# R7FA8M1AH register map
Vendor: Renesas; Series: RA8; File version: 1.2
CPU: CM85 r0p0, little endian, MPU, FPU, VTOR, 4 interrupt priority bits
Registers are 32-bit, read-write, reset 0x0 unless marked. A register's access mark holds for its fields unless they carry their own. Offsets are from the block's base; [hi:lo] are bit positions; {n}, {i} and the like mark numbered series; 'fields as' and 'values as' point back to an identical list.

## RTC — Realtime Clock
Base 0x40202000
Same registers: RTC_NS 0x50202000
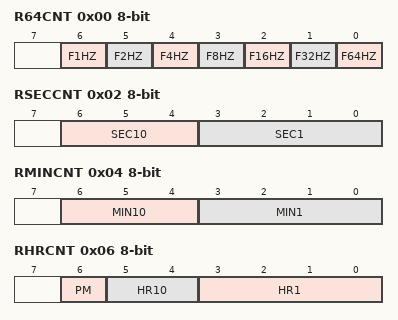
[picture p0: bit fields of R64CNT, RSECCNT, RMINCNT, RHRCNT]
0x00 R64CNT 8-bit ro (reset mask 0x80) — 64-Hz Counter
  [6] F1HZ — 1Hz
  [5] F2HZ — 2Hz
  [4] F4HZ — 4Hz
  [3] F8HZ — 8Hz
  [2] F16HZ — 16Hz
  [1] F32HZ — 32Hz
  [0] F64HZ — 64Hz
0x02 BCNT0 8-bit reset not defined (alternate view of RSECCNT) — Binary Counter 0
  [7:0] BCNT0 — The BCNT0 counter is a readable/writable 32-bit binary counter b7 to b0.
0x02 RSECCNT 8-bit reset not defined — Second Counter
  [6:4] SEC10 — 10-Second Count Counts from 0 to 5 for 60-second counting.
  [3:0] SEC1 — 1-Second Count Counts from 0 to 9 every second. When a carry is generated, 1 is added to the tens place.
0x04 BCNT1 8-bit reset not defined (alternate view of RMINCNT) — Binary Counter 1
  [7:0] BCNT1 — The BCNT1 counter is a readable/writable 32-bit binary counter b15 to b8.
0x04 RMINCNT 8-bit reset not defined — Minute Counter
  [6:4] MIN10 — 10-Minute Count Counts from 0 to 5 for 60-minute counting.
  [3:0] MIN1 — 1-Minute Count Counts from 0 to 9 every minute. When a carry is generated, 1 is added to the tens place.
0x06 BCNT2 8-bit reset not defined (alternate view of RHRCNT) — Binary Counter 2
  [7:0] BCNT2 — The BCNT2 counter is a readable/writable 32-bit binary counter b23 to b16.
0x06 RHRCNT 8-bit reset not defined — Hour Counter
  [6] PM — Time Counter Setting for a.m./p.m.
    0=a.m; 1=p.m
  [5:4] HR10 — 10-Hour Count Counts from 0 to 2 once per carry from the ones place.
  [3:0] HR1 — 1-Hour Count Counts from 0 to 9 once per hour. When a carry is generated, 1 is added to the tens place.
0x08 BCNT3 8-bit reset not defined (alternate view of RWKCNT) — Binary Counter 3
  [7:0] BCNT3 — The BCNT3 counter is a readable/writable 32-bit binary counter b31 to b24.
0x08 RWKCNT 8-bit reset not defined — Day-of-Week Counter
  [2:0] DAYW — Day-of-Week Counting
    0=Sunday; 1=Monday; 2=Tuesday; 3=Wednesday; 4=Thursday; 5=Friday; 6=Saturday; 7=Setting Prohibited
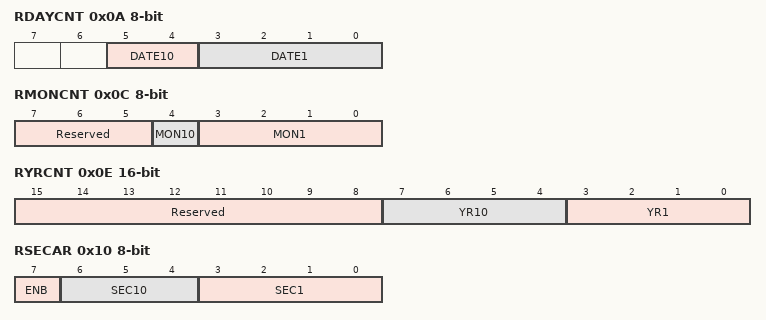
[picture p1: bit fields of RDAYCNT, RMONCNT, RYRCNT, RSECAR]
0x0A RDAYCNT 8-bit (reset mask 0xC0) — Day Counter
  [5:4] DATE10 — 10-Day Count Counts from 0 to 3 once per carry from the ones place.
  [3:0] DATE1 — 1-Day Count Counts from 0 to 9 once per day. When a carry is generated, 1 is added to the tens place.
0x0C RMONCNT 8-bit (reset mask 0xE0) — Month Counter
  [7:5] Reserved — These bits are read as 000. The write value should be 000.
  [4] MON10 — 10-Month Count Counts from 0 to 1 once per carry from the ones place.
  [3:0] MON1 — 1-Month Count Counts from 0 to 9 once per month. When a carry is generated, 1 is added to the tens place.
0x0E RYRCNT 16-bit (reset mask 0xFF00) — Year Counter
  [15:8] Reserved — These bits are read as 00000000. The write value should be 00000000.
  [7:4] YR10 — 10-Year Count Counts from 0 to 9 once per carry from ones place. When a carry is generated in the tens place, 1 is added to the hundreds place.
  [3:0] YR1 — 1-Year Count Counts from 0 to 9 once per year. When a carry is generated, 1 is added to the tens place.
0x10 BCNT0AR 8-bit reset not defined (alternate view of RSECAR) — Binary Counter 0 Alarm Register
  [7:0] BCNT0AR — he BCNT0AR counter is a readable/writable alarm register corresponding to 32-bit binary counter b7 to b0.
0x10 RSECAR 8-bit reset not defined — Second Alarm Register
  [7] ENB — Compare enable
    0=The register value is not compared with the RSECCNT counter value; 1=The register value is compared with the RSECCNT counter value
  [6:4] SEC10 — 10-Seconds Value for the tens place of seconds
  [3:0] SEC1 — 1-Second Value for the ones place of seconds
0x12 BCNT1AR 8-bit reset not defined (alternate view of RMINAR) — Binary Counter 1 Alarm Register
  [7:0] BCNT1AR — he BCNT1AR counter is a readable/writable alarm register corresponding to 32-bit binary counter b15 to b8.
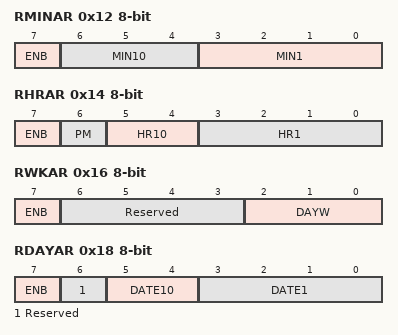
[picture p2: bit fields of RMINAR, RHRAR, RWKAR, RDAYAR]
0x12 RMINAR 8-bit reset not defined — Minute Alarm Register
  [7] ENB — Compare enable
    0=The register value is not compared with the RMINCNT counter value; 1=The register value is compared with the RMINCNT counter value
  [6:4] MIN10 — 10-Minute Count Value for the tens place of minutes
  [3:0] MIN1 — 1-Minute Count Value for the ones place of minutes
0x14 BCNT2AR 8-bit reset not defined (alternate view of RHRAR) — Binary Counter 2 Alarm Register
  [7:0] BCNT2AR — The BCNT2AR counter is a readable/writable 32-bit binary counter b23 to b16.
0x14 RHRAR 8-bit reset not defined — Hour Alarm Register
  [7] ENB — Compare enable
    0=The register value is not compared with the RHRCNT counter value; 1=The register value is compared with the RHRCNT counter value
  [6] PM — Time Counter Setting for a.m./p.m.
    0=a.m; 1=p.m
  [5:4] HR10 — 10-Hour Count Value for the tens place of hours
  [3:0] HR1 — 1-Hour Count Value for the ones place of hours
0x16 BCNT3AR 8-bit reset not defined (alternate view of RWKAR) — Binary Counter 3 Alarm Register
  [7:0] BCNT3AR — The BCNT3AR counter is a readable/writable 32-bit binary counter b31 to b24.
0x16 RWKAR 8-bit reset not defined — Day-of-Week Alarm Register
  [7] ENB — Compare enable
    0=The register value is not compared with the RWKCNT counter value; 1=The register value is compared with the RWKCNT counter value
  [6:3] Reserved — These bits are read as 0000. The write value should be 0000.
  [2:0] DAYW — Day-of-Week Counting
    values as RWKCNT.DAYW
0x18 BCNT0AER 8-bit reset not defined (alternate view of RDAYAR) — Binary Counter 0 Alarm Enable Register
  [7:0] ENB — The BCNT0AER register is a readable/writable register for setting the alarm enable corresponding to 32-bit binary counter b7 to b0.
0x18 RDAYAR 8-bit reset not defined — Date Alarm Register
  [7] ENB — Compare enable
    0=The register value is not compared with the RDAYCNT counter value; 1=The register value is compared with the RDAYCNT counter value
  [6] Reserved — This bit is read as 0. The write value should be 0.
  [5:4] DATE10 — 10 Days Value for the tens place of days
  [3:0] DATE1 — 1 Day Value for the ones place of days
0x1A BCNT1AER 8-bit reset not defined (alternate view of RMONAR) — Binary Counter 1 Alarm Enable Register
  [7:0] ENB — The BCNT1AER register is a readable/writable register for setting the alarm enable corresponding to 32-bit binary counter b15 to b8.
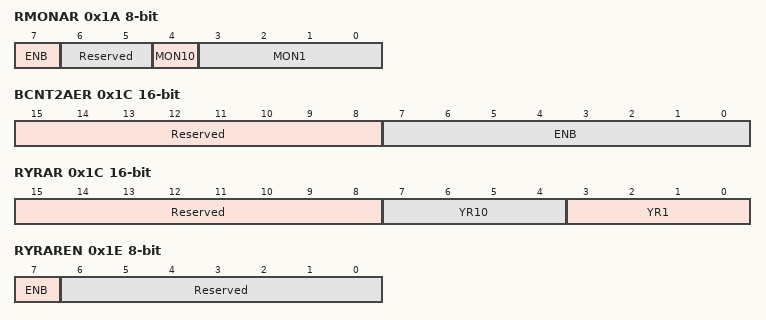
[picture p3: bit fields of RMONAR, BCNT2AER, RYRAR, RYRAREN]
0x1A RMONAR 8-bit reset not defined — Month Alarm Register
  [7] ENB — Compare enable
    0=The register value is not compared with the RMONCNT counter value; 1=The register value is compared with the RMONCNT counter value
  [6:5] Reserved — These bits are read as 00. The write value should be 00.
  [4] MON10 — 10 Months Value for the tens place of months
  [3:0] MON1 — 1 Month Value for the ones place of months
0x1C BCNT2AER 16-bit (reset mask 0xFF00) (alternate view of RYRAR) — Binary Counter 2 Alarm Enable Register
  [15:8] Reserved — These bits are read as 00000000. The write value should be 00000000.
  [7:0] ENB — The BCNT2AER register is a readable/writable register for setting the alarm enable corresponding to 32-bit binary counter b23 to b16.
0x1C RYRAR 16-bit (reset mask 0xFF00) — Year Alarm Register
  [15:8] Reserved — These bits are read as 00000000. The write value should be 00000000.
  [7:4] YR10 — 10 Years Value for the tens place of years
  [3:0] YR1 — 1 Year Value for the ones place of years
0x1E BCNT3AER 8-bit reset not defined (alternate view of RYRAREN) — Binary Counter 3 Alarm Enable Register
  [7:0] ENB — The BCNT3AER register is a readable/writable register for setting the alarm enable corresponding to 32-bit binary counter b31 to b24.
0x1E RYRAREN 8-bit reset not defined — Year Alarm Enable Register
  [7] ENB — Compare enable
    0=The register value is not compared with the RYRCNT counter value; 1=The register value is compared with the RYRCNT counter value
  [6:0] Reserved — These bits are read as 0000000. The write value should be 0000000.
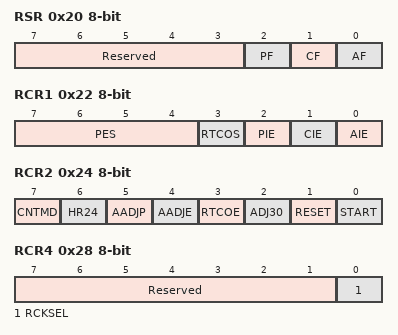
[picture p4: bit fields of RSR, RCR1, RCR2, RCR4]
0x20 RSR 8-bit (reset mask 0x7) — RTC Start Register
  [7:3] Reserved — These bits are read as 00000. The write value should be 00000.
  [2] PF — Interrupt period
  [1] CF — Carry flag
  [0] AF — Alarm flag
0x22 RCR1 8-bit (reset mask 0xA) — RTC Control Register 1
  [7:4] PES — Periodic Interrupt Select
    6=A periodic interrupt is generated every 1/256 second((RCR4.RCKSEL = 0)./A periodic interrupt is generated every 1/128 second((RCR4.RCKSEL = 1); 7=A periodic interrupt is generated every 1/128 second; 8=A periodic interrupt is generated every 1/64 second; 9=A periodic interrupt is generated every 1/32 second; 10=A periodic interrupt is generated every 1/16 second; 11=A periodic interrupt is generated every 1/8 second; 12=A periodic interrupt is generated every 1/4 second; 13=A periodic interrupt is generated every 1/2 second; 14=A periodic interrupt is generated every 1 second; 15=A periodic interrupt is generated every 2 seconds; other=others (No periodic interrupts are generated.)
  [3] RTCOS — RTCOUT Output Select
    0=RTCOUT outputs 1 Hz; 1=RTCOUT outputs 64 Hz
  [2] PIE — Periodic Interrupt Enable
    0=A periodic interrupt request is disabled; 1=A periodic interrupt request is enabled
  [1] CIE — Carry Interrupt Enable
    0=A carry interrupt request is disabled; 1=A carry interrupt request is enabled
  [0] AIE — Alarm Interrupt Enable
    0=An alarm interrupt request is disabled; 1=An alarm interrupt request is enabled
0x24 RCR2 8-bit (reset mask 0xE) — RTC Control Register 2
  [7] CNTMD — Count Mode Select
    0=The calendar count mode; 1=The binary count mode
  [6] HR24 — Hours Mode
    0=The RTC operates in 12-hour mode; 1=The RTC operates in 24-hour mode
  [5] AADJP — Automatic Adjustment Period Select (When the LOCO clock is selected, the setting of this bit is disabled.)
    0=The RADJ.ADJ[5:0] setting value is adjusted from the count value of the prescaler every minute; 1=The RADJ.ADJ[5:0] setting value is adjusted from the count value of the prescaler every 10 seconds
  [4] AADJE — Automatic Adjustment Enable (When the LOCO clock is selected, the setting of this bit is disabled.)
    0=Automatic adjustment is disabled; 1=Automatic adjustment is enabled
  [3] RTCOE — RTCOUT Output Enable
    0=RTCOUT output disabled; 1=RTCOUT output enabled
  [2] ADJ30 — 30-Second Adjustment
    0=Writing is invalid.(write) / In normal time operation, or 30-second adjustment has completed.(read); 1=30-second adjustment is executed.(write) / During 30-second adjustment.(read)
  [1] RESET — RTC Software Reset
    0=Writing is invalid.(write) / In normal time operation, or an RTC software reset has completed.(read); 1=The prescaler and the target registers for RTC software reset *1 are initialized.(write) / During an RTC software reset.(read)
  [0] START
    0=Prescaler and time counter are stopped; 1=Prescaler and time counter operate normally
0x26 RCR3 8-bit — RTC Control Register 3
0x28 RCR4 8-bit (reset mask 0xFE) — RTC Control Register 4
  [7:1] Reserved — These bits are read as 0000000. The write value should be 0000000.
  [0] RCKSEL — Count Source Select
    0=Sub-clock oscillator is selected; 1=LOCO clock oscillator is selected
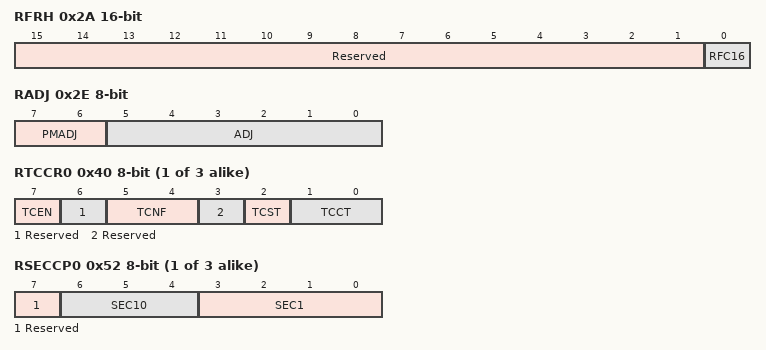
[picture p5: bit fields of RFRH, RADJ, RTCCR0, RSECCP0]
0x2A RFRH 16-bit (reset mask 0xFFFE) — Frequency Register H
  [15:1] Reserved — These bits are read as 000000000000000. The write value should be 000000000000000.
  [0] RFC16 — Frequency Comparison Value (b16) To generate the operating clock from the LOCOclock, this bit sets the comparison value of the 128-Hz clock cycle.
0x2C RFRL 16-bit reset not defined — Frequency Register L
  [15:0] RFC — Frequency Comparison Value(b15-b0) To generate the operating clock from the main clock, this bit sets the comparison value of the 128-Hz clock cycle.
0x2E RADJ 8-bit reset not defined — Time Error Adjustment Register
  [7:6] PMADJ — Plus-Minus
    0=Adjustment is not performed; 1=Adjustment is performed by the addition to the prescaler; 2=Adjustment is performed by the subtraction from the prescaler; 3=Setting prohibited
  [5:0] ADJ — Adjustment Value These bits specify the adjustment value from the prescaler.
0x32 RTEST 8-bit
0x38 RKEY 8-bit
{0x40+2i} RTCCR{i} (i=0..2) 8-bit reset not defined — Time Capture Control Register {i}
  [7] TCEN — Time Capture Event Input Pin Enable
    0=The RTCIC pin is disabled as the time capture event input; 1=The RTCIC pin is enabled as the time capture event input
  [6] Reserved — This bit is read as 0. The write value should be 0.
  [5:4] TCNF — Time Capture Noise Filter Control
    0=The noise filter is off; 1=Setting prohibited; 2=The noise filter is on (count source); 3=The noise filter is on (count source by divided by 32)
  [3] Reserved — This bit is read as 0. The write value should be 0.
  [2] TCST write-0-clears read-modifies — Time Capture Status
    0=No event is detected; 1=An event is detected
  [1:0] TCCT — Time Capture Control
    0=No event is detected; 1=Rising edge is detected; 2=Falling edge is detected; 3=Both edges are detected
{0x52+0x10*i} BCNT0CP{i} (i=0..2) 8-bit ro reset not defined (alternate view of RSECCP{i}) — BCNT0 Capture Register {i}
  [7:0] BCNT0CP — BCNT0CP is a read-only register that captures the BCNT0 value when a time capture event is detected.
{0x52+0x10*i} RSECCP{i} (i=0..2) 8-bit ro reset not defined — Second Capture Register {i}
  [7] Reserved — This bit is read as 0.
  [6:4] SEC10 — 10-Second Capture Capture value for the tens place of seconds
  [3:0] SEC1 — 1-Second Capture Capture value for the ones place of seconds
{0x54+0x10*i} BCNT1CP{i} (i=0..2) 8-bit ro reset not defined (alternate view of RMINCP{i}) — BCNT1 Capture Register {i}
  [7:0] BCNT1CP — BCNT1CP is a read-only register that captures the BCNT1 value when a time capture event is detected.
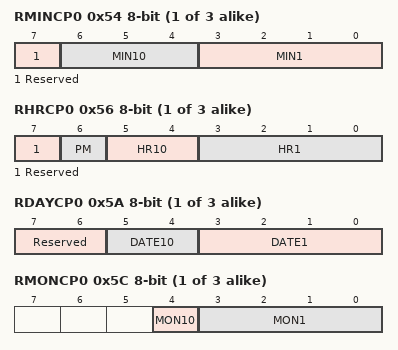
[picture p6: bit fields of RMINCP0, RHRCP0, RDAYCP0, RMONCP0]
{0x54+0x10*i} RMINCP{i} (i=0..2) 8-bit ro reset not defined — Minute Capture Register {i}
  [7] Reserved — This bit is read as 0.
  [6:4] MIN10 — 10-Minute Capture Capture value for the tens place of minutes
  [3:0] MIN1 — 1-Minute Capture Capture value for the ones place of minutes
{0x56+0x10*i} BCNT2CP{i} (i=0..2) 8-bit ro reset not defined (alternate view of RHRCP{i}) — BCNT2 Capture Register {i}
  [7:0] BCNT2CP — BCNT2CP is a read-only register that captures the BCNT2 value when a time capture event is detected.
{0x56+0x10*i} RHRCP{i} (i=0..2) 8-bit ro reset not defined — Hour Capture Register {i}
  [7] Reserved — This bit is read as 0.
  [6] PM — A.m./p.m. select for time counter setting.
    0=a.m; 1=p.m
  [5:4] HR10 — 10-Minute Capture Capture value for the tens place of minutes
  [3:0] HR1 — 1-Minute Capture Capture value for the ones place of minutes
{0x5A+0x10*i} BCNT3CP{i} (i=0..2) 8-bit ro reset not defined (alternate view of RDAYCP{i}) — BCNT3 Capture Register {i}
  [7:0] BCNT3CP — BCNT3CP is a read-only register that captures the BCNT3 value when a time capture event is detected.
{0x5A+0x10*i} RDAYCP{i} (i=0..2) 8-bit ro reset not defined — Date Capture Register {i}
  [7:6] Reserved — These bits are read as 00.
  [5:4] DATE10 — 10-Day Capture Capture value for the tens place of minutes
  [3:0] DATE1 — 1-Day Capture Capture value for the ones place of minutes
{0x5C+0x10*i} RMONCP{i} (i=0..2) 8-bit ro reset not defined — Month Capture Register {i}
  [4] MON10 — 10-Month Capture Capture value for the tens place of months
  [3:0] MON1 — 1-Month Capture Capture value for the ones place of months
